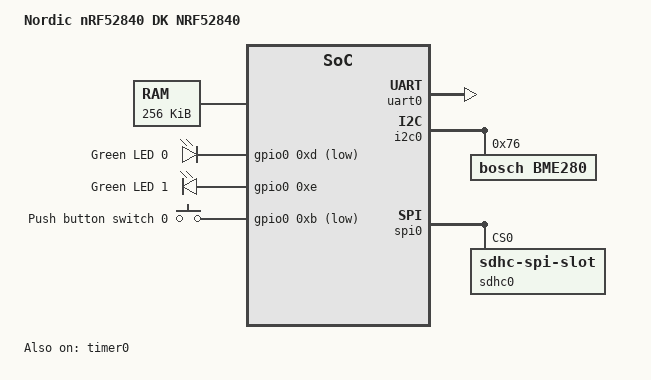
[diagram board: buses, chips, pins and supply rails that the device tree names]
/dts-v1/;
/ {
	model = "Nordic nRF52840 DK NRF52840";
	aliases {
		led0 = &led0;
		sw0 = &button0;
	};
	chosen {
		zephyr,console = &uart0;
		zephyr,flash = &flash0;
		zephyr,sram = &sram0;
	};
	cpus {
		#address-cells = <0x1>;
		#size-cells = <0x0>;
		cpu@0 {
			device_type = "cpu";
			compatible = "arm,cortex-m4f";
			reg = <0x0>;
		};
	};
	sram0: memory@20000000 {
		device_type = "memory";
		reg = <0x20000000 0x40000>;
	};
	soc {
		gpio0: gpio@50000000 {
			compatible = "nordic,nrf-gpio";
			reg = <0x50000000 0x200>;
			#gpio-cells = <0x2>;
			gpio-controller;
			phandle = <0x6>;
		};
		uart0: uart@40002000 {
			compatible = "nordic,nrf-uarte";
			reg = <0x40002000 0x1000>;
			interrupts = <0x2 0x1>;
			status = "okay";
			phandle = <0x7>;
		};
		timer0: timer@40008000 {
			compatible = "nordic,nrf-timer";
			reg = <0x40008000 0x1000>;
			interrupts = <0x8 0x1>;
			status = "okay";
		};
		flash_controller: flash-controller@4001e000 {
			compatible = "nordic,nrf52-flash-controller";
			reg = <0x4001e000 0x1000>;
			#address-cells = <0x1>;
			#size-cells = <0x1>;
			flash0: flash@0 {
				compatible = "soc-nv-flash";
				reg = <0x0 0x100000>;
			};
		};
		i2c0: i2c@40003000 {
			compatible = "nordic,nrf-twim";
			reg = <0x40003000 0x1000>;
			#address-cells = <0x1>;
			#size-cells = <0x0>;
			status = "okay";
			phandle = <0x8>;
			bme280@76 {
				compatible = "bosch,bme280";
				reg = <0x76>;
				status = "okay";
			};
			disabled_sensor@77 {
				compatible = "ti,ina219";
				reg = <0x77>;
				status = "disabled";
			};
		};
		spi0: spi@40004000 {
			compatible = "nordic,nrf-spim";
			reg = <0x40004000 0x1000>;
			#address-cells = <0x1>;
			#size-cells = <0x0>;
			status = "okay";
			phandle = <0x9>;
			sdhc0: sdhc@0 {
				compatible = "zephyr,sdhc-spi-slot";
				reg = <0x0>;
				status = "okay";
			};
		};
	};
	leds {
		compatible = "gpio-leds";
		led0: led_0 {
			gpios = <&gpio0 0xd 0x1>;
			label = "Green LED 0";
		};
		led1: led_1 {
			gpios = <&gpio0 0xe 0x0>;
			label = "Green LED 1";
		};
	};
	buttons {
		compatible = "gpio-keys";
		button0: button_0 {
			gpios = <&gpio0 0xb 0x1>;
			label = "Push button switch 0";
		};
	};
};
